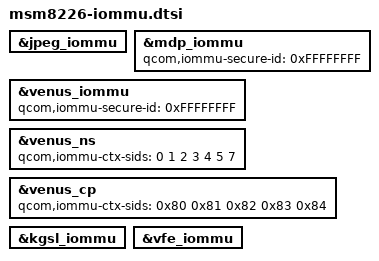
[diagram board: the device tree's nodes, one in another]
/* Copyright (c) 2013, The Linux Foundation. All rights reserved.
 *
 * This program is free software; you can redistribute it and/or modify
 * it under the terms of the GNU General Public License version 2 and
 * only version 2 as published by the Free Software Foundation.
 *
 * This program is distributed in the hope that it will be useful,
 * but WITHOUT ANY WARRANTY; without even the implied warranty of
 * MERCHANTABILITY or FITNESS FOR A PARTICULAR PURPOSE.  See the
 * GNU General Public License for more details.
 */

/include/ "msm-iommu-v1.dtsi"

&jpeg_iommu {
	status = "ok";
};

&mdp_iommu {
	status = "ok";
	/* HACK: set to -1 during pre-si due to lack of TZ */
	qcom,iommu-secure-id = <0xFFFFFFFF>;
};

&venus_iommu {
	status = "ok";
	/* HACK: set to -1 during pre-si due to lack of TZ */
	qcom,iommu-secure-id = <0xFFFFFFFF>;
};

&venus_ns {
	   qcom,iommu-ctx-sids = <0 1 2 3 4 5 7>;
};

&venus_cp {
	   qcom,iommu-ctx-sids = <0x80 0x81 0x82 0x83 0x84>;
};

&kgsl_iommu {
	status = "ok";
};

&vfe_iommu {
	status = "ok";
};
